# SPI3 register map
Registers from a debugger description file.
Registers are 32-bit, access not given, no defined reset value unless marked. A register's access mark holds for its fields unless they carry their own. Addresses are absolute; registers are grouped by the start of their names; lines under a group give offsets from that group; [hi:lo] are bit positions; {n}, {i} and the like mark numbered series; 'fields as' and 'values as' point back to an identical list; <NAME> marks a mode.

## SPI3
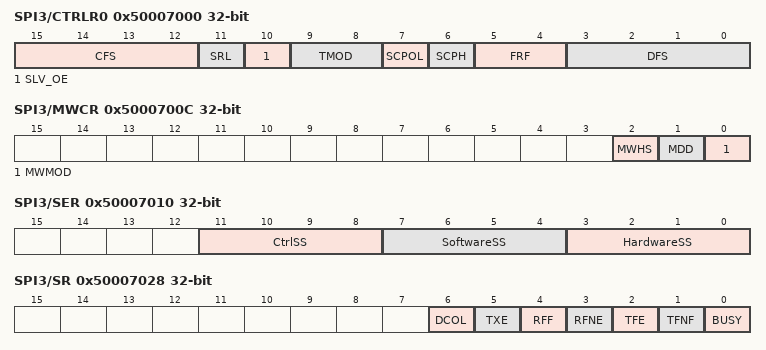
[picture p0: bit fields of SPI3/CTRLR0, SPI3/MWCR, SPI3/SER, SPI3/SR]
0x50007000 SPI3/CTRLR0
  [15:12] CFS, [11] SRL, [10] SLV_OE, [9:8] TMOD, [7] SCPOL, [6] SCPH, [5:4] FRF, [3:0] DFS
0x50007004 SPI3/CTRLR1
  [15:0] NDF
0x50007008 SPI3/SSIENR
  [0] SSIENR
0x5000700C SPI3/MWCR
  [2] MWHS, [1] MDD, [0] MWMOD
0x50007010 SPI3/SER
  [11:8] CtrlSS, [7:4] SoftwareSS, [3:0] HardwareSS
0x50007014 SPI3/BAUDR
  [15:0] SCKDV
0x50007018 SPI3/TXFTLR
  [3:0] TFT
0x5000701C SPI3/RXFTLR
  [3:0] RFT
0x50007020 SPI3/TXFLR ro
  [3:0] TXTFL
0x50007024 SPI3/RXFLR ro
  [3:0] RXTFL
0x50007028 SPI3/SR ro
  [6] DCOL, [5] TXE, [4] RFF, [3] RFNE, [2] TFE, [1] TFNF, [0] BUSY
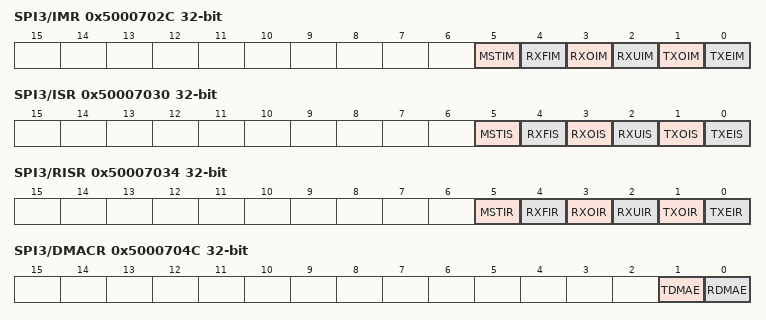
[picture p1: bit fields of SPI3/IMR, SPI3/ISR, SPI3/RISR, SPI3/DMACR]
0x5000702C SPI3/IMR
  [5] MSTIM, [4] RXFIM, [3] RXOIM, [2] RXUIM, [1] TXOIM, [0] TXEIM
0x50007030 SPI3/ISR ro
  [5] MSTIS, [4] RXFIS, [3] RXOIS, [2] RXUIS, [1] TXOIS, [0] TXEIS
0x50007034 SPI3/RISR ro
  [5] MSTIR, [4] RXFIR, [3] RXOIR, [2] RXUIR, [1] TXOIR, [0] TXEIR
0x50007038 SPI3/TXOICR ro
  [0] TXOICR
0x5000703C SPI3/RXOICR ro
  [0] RXOICR
0x50007040 SPI3/RXUICR ro
  [0] RXUICR
0x50007044 SPI3/MSTICR ro
  [0] MSTICR
0x50007048 SPI3/ICR ro
  [0] ICR
0x5000704C SPI3/DMACR
  [1] TDMAE, [0] RDMAE
0x50007050 SPI3/DMATDLR
  [3:0] DMATDLR
0x50007054 SPI3/DMARDLR
  [3:0] DMARDLR
0x50007058 SPI3/IDR ro
  [31:0] ICR
0x5000705C SPI3/SSI_COMP_VERSION ro
0x50007060 SPI3/DR
  [15:0] DR
0x500070F0 SPI3/RX_SAMPLE_DLY
  [7:0] RX_Sample_Delay
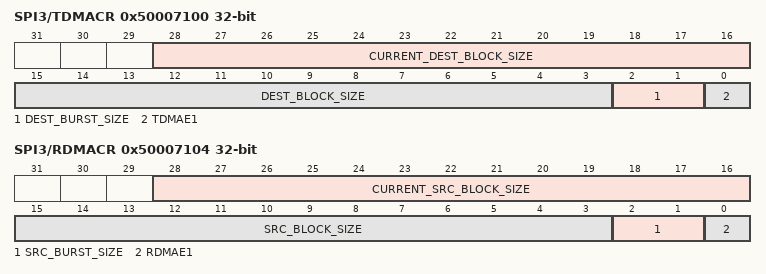
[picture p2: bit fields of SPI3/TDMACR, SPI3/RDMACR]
0x50007100 SPI3/TDMACR
  [28:16] CURRENT_DEST_BLOCK_SIZE, [15:3] DEST_BLOCK_SIZE, [2:1] DEST_BURST_SIZE, [0] TDMAE1
0x50007104 SPI3/RDMACR
  [28:16] CURRENT_SRC_BLOCK_SIZE, [15:3] SRC_BLOCK_SIZE, [2:1] SRC_BURST_SIZE, [0] RDMAE1
